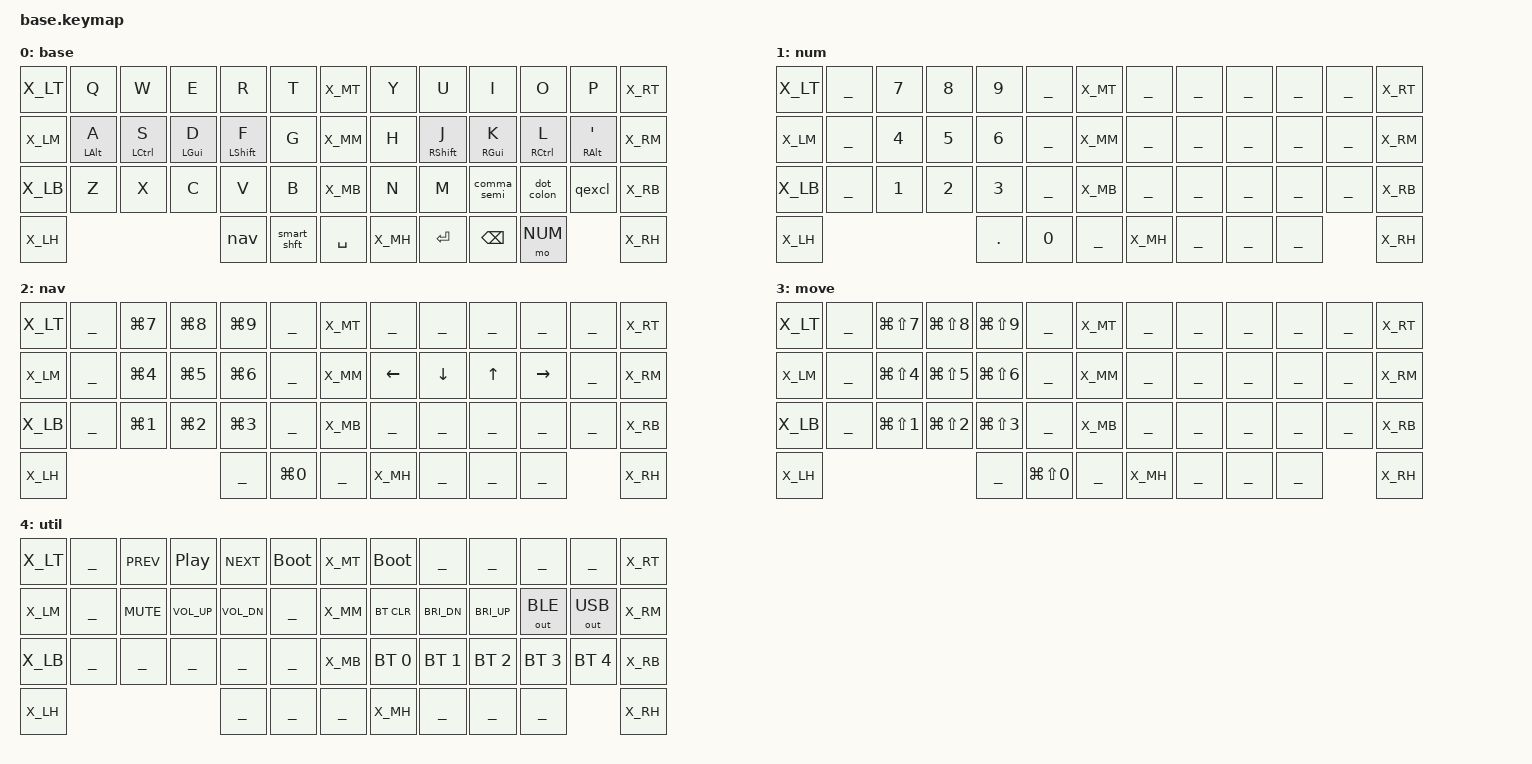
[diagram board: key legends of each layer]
#include <behaviors.dtsi>
#include <dt-bindings/zmk/bt.h>
#include <dt-bindings/zmk/keys.h>
#include <dt-bindings/zmk/outputs.h>

#define BASE    0
#define NUM     1
#define NAV     2
#define MV      3
#define UTIL    4

#include "extras.h"
#include "setup.dtsi"
#include "behaviors.dtsi"
#include "combos.dtsi"

/ {
    keymap {
        compatible = "zmk,keymap";
        base {
            display-name = "base";
            bindings = <
//╭──────╮  ╭───────────────────┬───────────────────┬───────────────────┬───────────────────┬───────────────────╮                      ╭──────╮                      ╭───────────────────┬───────────────────┬───────────────────┬───────────────────┬───────────────────╮   ╭──────╮
    X_LT      &kp Q               &kp W               &kp E               &kp R               &kp T                                      X_MT                          &kp Y               &kp U               &kp I               &kp O               &kp P                   X_RT
//├──────┤  ├───────────────────┼───────────────────┼───────────────────┼───────────────────┼───────────────────┤                      ├──────┤                      ├───────────────────┼───────────────────┼───────────────────┼───────────────────┼───────────────────┤   ├──────┤
    X_LM      &hml LALT A         &hml LCTRL S        &hml LGUI D         &hml LSHIFT F       &kp G                                      X_MM                          &kp H               &hmr RSHIFT J       &hmr RGUI K         &hmr RCTRL L        &hmr RALT SQT           X_RM
//├──────┤  ├───────────────────┼───────────────────┼───────────────────┼───────────────────┼───────────────────┤                      ├──────┤                      ├───────────────────┼───────────────────┼───────────────────┼───────────────────┼───────────────────┤   ├──────┤
    X_LB      &kp Z               &kp X               &kp C               &kp V               &kp B                                      X_MB                          &kp N               &kp M               &comma_semi         &dot_colon          &qexcl                  X_RB
//├──────┤  ╰───────────────────┴───────────────────┴───────────────────┼───────────────────┼───────────────────┼───────────────────╮  ├──────┤  ╭───────────────────┼───────────────────┼───────────────────┼───────────────────┴───────────────────┴───────────────────╯   ├──────┤
    X_LH                                                                  &nav                &smart_shft         &kp SPACE              X_MH      &kp RET             &kp BSPC            &mo NUM                                                                             X_RH
//╰──────╯                                                              ╰───────────────────┴───────────────────┴───────────────────╯  ╰──────╯  ╰───────────────────┴───────────────────┴───────────────────╯                                                               ╰──────╯
            >;
        };

        num {
            display-name = "num";
            bindings = <
//╭──────╮  ╭───────────────────┬───────────────────┬───────────────────┬───────────────────┬───────────────────╮                     ╭──────╮                      ╭───────────────────┬───────────────────┬───────────────────┬───────────────────┬───────────────────╮  ╭──────╮
    X_LT      ___                 &kp N7              &kp N8              &kp N9              ___                                       X_MT                          ___                 ___                 ___                 ___                 ___                    X_RT
//├──────┤  ├───────────────────┼───────────────────┼───────────────────┼───────────────────┼───────────────────┤                     ├──────┤                      ├───────────────────┼───────────────────┼───────────────────┼───────────────────┼───────────────────┤  ├──────┤
    X_LM      ___                 &kp N4              &kp N5              &kp N6              ___                                       X_MM                          ___                 ___                 ___                 ___                 ___                    X_RM
//├──────┤  ├───────────────────┼───────────────────┼───────────────────┼───────────────────┼───────────────────┤                     ├──────┤                      ├───────────────────┼───────────────────┼───────────────────┼───────────────────┼───────────────────┤  ├──────┤
    X_LB      ___                 &kp N1              &kp N2              &kp N3              ___                                       X_MB                          ___                 ___                 ___                 ___                 ___                    X_RB
//├──────┤  ╰───────────────────┴───────────────────┴───────────────────┼───────────────────┼───────────────────┼───────────────────╮ ├──────┤  ╭───────────────────┼───────────────────┼───────────────────┼───────────────────┴───────────────────┴───────────────────╯  ├──────┤
    X_LH                                                                  &kp DOT             &kp N0              ___                   X_MH      ___                 ___                 ___                                                                                X_RH
//╰──────╯                                                              ╰───────────────────┴───────────────────┴───────────────────╯ ╰──────╯  ╰───────────────────┴───────────────────┴───────────────────╯                                                              ╰──────╯
            >;
        };

        nav {
            display-name = "nav";
            bindings = <
//╭──────╮  ╭───────────────────┬───────────────────┬───────────────────┬───────────────────┬───────────────────╮                      ╭──────╮                      ╭───────────────────┬───────────────────┬───────────────────┬───────────────────┬───────────────────╮  ╭──────╮ 
    X_LT      ___                 &kp LG(N7)          &kp LG(N8)          &kp LG(N9)          ___                                        X_MT                          ___                 ___                 ___                 ___                 ___                     X_RT
//├──────┤  ├───────────────────┼───────────────────┼───────────────────┼───────────────────┼───────────────────┤                      ├──────┤                      ├───────────────────┼───────────────────┼───────────────────┼───────────────────┼───────────────────┤  ├──────┤ 
    X_LM      ___                 &kp LG(N4)          &kp LG(N5)          &kp LG(N6)          ___                                        X_MM                          &kp LEFT            &kp DOWN            &kp UP              &kp RIGHT           ___                     X_RM
//├──────┤  ├───────────────────┼───────────────────┼───────────────────┼───────────────────┼───────────────────┤                      ├──────┤                      ├───────────────────┼───────────────────┼───────────────────┼───────────────────┼───────────────────┤  ├──────┤ 
    X_LB      ___                 &kp LG(N1)          &kp LG(N2)          &kp LG(N3)          ___                                        X_MB                          ___                 ___                 ___                 ___                 ___                    X_RB
//├──────┤  ╰───────────────────┴───────────────────┴───────────────────┼───────────────────┼───────────────────┼───────────────────╮  ├──────┤  ╭───────────────────┼───────────────────┼───────────────────┼───────────────────┴───────────────────┴───────────────────╯  ├──────┤ 
    X_LH                                                                  ___                 &kp LG(N0)          ___                    X_MH      ___                 ___                 ___                                                                                X_RH
//╰──────╯                                                              ╰───────────────────┴───────────────────┴───────────────────╯  ╰──────╯  ╰───────────────────┴───────────────────┴───────────────────╯                                                              ╰──────╯ 
            >;
        };

        mv {
            display-name = "move";
            bindings = <
//╭──────╮  ╭───────────────────┬───────────────────┬───────────────────┬───────────────────┬───────────────────╮                      ╭──────╮                      ╭───────────────────┬───────────────────┬───────────────────┬───────────────────┬───────────────────╮  ╭──────╮
    X_LT      ___                 &kp LG(LS(N7))      &kp LG(LS(N8))      &kp LG(LS(N9))      ___                                        X_MT                          ___                 ___                 ___                 ___                 ___                    X_RT
//├──────┤  ├───────────────────┼───────────────────┼───────────────────┼───────────────────┼───────────────────┤                      ├──────┤                      ├───────────────────┼───────────────────┼───────────────────┼───────────────────┼───────────────────┤  ├──────┤
    X_LM      ___                 &kp LG(LS(N4))      &kp LG(LS(N5))      &kp LG(LS(N6))      ___                                        X_MM                          ___                 ___                 ___                 ___                 ___                    X_RM
//├──────┤  ├───────────────────┼───────────────────┼───────────────────┼───────────────────┼───────────────────┤                      ├──────┤                      ├───────────────────┼───────────────────┼───────────────────┼───────────────────┼───────────────────┤  ├──────┤
    X_LB      ___                 &kp LG(LS(N1))      &kp LG(LS(N2))      &kp LG(LS(N3))      ___                                        X_MB                          ___                 ___                 ___                 ___                 ___                    X_RB
//├──────┤  ╰───────────────────┴───────────────────┴───────────────────┼───────────────────┼───────────────────┼───────────────────╮  ├──────┤  ╭───────────────────┼───────────────────┼───────────────────┼───────────────────┴───────────────────┴───────────────────╯  ├──────┤
    X_LH                                                                  ___                 &kp LG(LS(N0))      ___                    X_MH      ___                 ___                 ___                                                                                X_RH
//╰──────╯                                                              ╰───────────────────┴───────────────────┴───────────────────╯  ╰──────╯  ╰───────────────────┴───────────────────┴───────────────────╯                                                              ╰──────╯
            >;
        };

        util {
            display-name = "util";
            bindings = <
//╭──────╮  ╭───────────────────┬───────────────────┬───────────────────┬───────────────────┬───────────────────╮                      ╭──────╮                      ╭───────────────────┬───────────────────┬───────────────────┬───────────────────┬───────────────────╮  ╭──────╮ 
    X_LT      ___                 &kp C_PREV          &kp C_PLAY_PAUSE    &kp C_NEXT          &bootloader                                X_MT                          &bootloader         ___                 ___                 ___                 ___                    X_RT
//├──────┤  ├───────────────────┼───────────────────┼───────────────────┼───────────────────┼───────────────────┤                      ├──────┤                      ├───────────────────┼───────────────────┼───────────────────┼───────────────────┼───────────────────┤  ├──────┤ 
    X_LM      ___                 &kp C_MUTE          &kp C_VOL_UP        &kp C_VOL_DN        ___                                        X_MM                          &bt BT_CLR          &kp C_BRI_DN        &kp C_BRI_UP        &out OUT_BLE        &out OUT_USB           X_RM
//├──────┤  ├───────────────────┼───────────────────┼───────────────────┼───────────────────┼───────────────────┤                      ├──────┤                      ├───────────────────┼───────────────────┼───────────────────┼───────────────────┼───────────────────┤  ├──────┤ 
    X_LB      ___                 ___                 ___                 ___                 ___                                        X_MB                          &bt BT_SEL 0        &bt BT_SEL 1        &bt BT_SEL 2        &bt BT_SEL 3        &bt BT_SEL 4           X_RB
//├──────┤  ╰───────────────────┴───────────────────┴───────────────────┼───────────────────┼───────────────────┼───────────────────╮  ├──────┤  ╭───────────────────┼───────────────────┼───────────────────┼───────────────────┴───────────────────┴───────────────────╯  ├──────┤ 
    X_LH                                                                  ___                 ___                 ___                    X_MH      ___                 ___                 ___                                                                                X_RH
//╰──────╯                                                              ╰───────────────────┴───────────────────┴───────────────────╯  ╰──────╯  ╰───────────────────┴───────────────────┴───────────────────╯                                                              ╰──────╯ 
            >;
        };
    };
};
